# STM32F030C6T6 register map
File version: 1.0
Registers are 32-bit, access not given, reset 0x0 unless marked. A register's access mark holds for its fields unless they carry their own. Offsets are from the block's base; [hi:lo] are bit positions; {n}, {i} and the like mark numbered series.

## I2C1
Base 0x40005400
Same registers: I2C2 0x40005800
0x00 CR1
  [23] PECEN, [22] ALERTEN, [21] SMBDEN, [20] SMBHEN, [19] GCEN, [17] NOSTRETCH, [16] SBC, [15] RXDMAEN, [14] TXDMAEN, [31:13] s, [12] ANFOFF, [11:8] DNF, [7] ERRIE, [6] TCIE, [5] STOPIE, [4] NACKIE, [3] ADDRIE, [2] RXIE, [1] TXIE, [0] PE
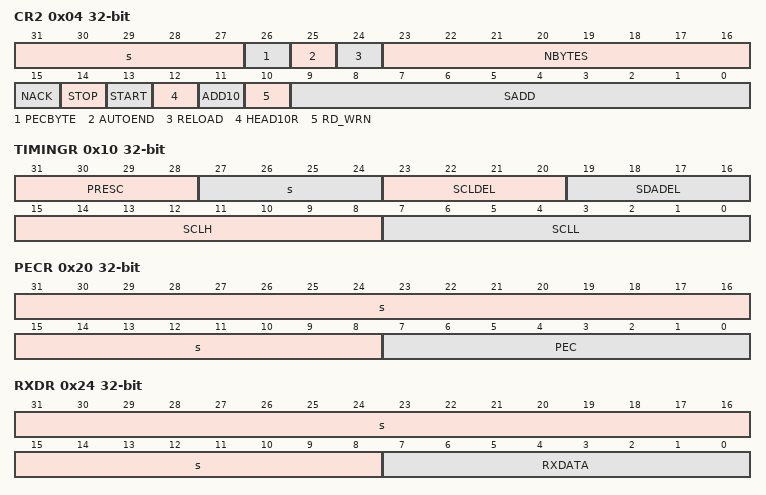
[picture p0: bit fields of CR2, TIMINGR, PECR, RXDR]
0x04 CR2
  [31:27] s, [26] PECBYTE, [25] AUTOEND, [24] RELOAD, [23:16] NBYTES, [15] NACK, [14] STOP, [13] START, [12] HEAD10R, [11] ADD10, [10] RD_WRN, [9:0] SADD
0x08 OAR1
  [15] OA1EN, [31:11] s, [10] OA1MODE, [9:0] OA1
0x0C OAR2
  [15] OA2EN, [10:8] OA2MSK, [7:1] OA2, [31:0] s
0x10 TIMINGR
  [31:28] PRESC, [27:24] s, [23:20] SCLDEL, [19:16] SDADEL, [15:8] SCLH, [7:0] SCLL
0x14 TIMEOUTR
  [31] TEXTEN, [27:16] TIMEOUTB, [15] TIMOUTEN, [30:13] s, [12] TIDLE, [11:0] TIMEOUTA
0x18 ISR
  [23:17] ADDCODE, [16] DIR, [15] BUSY, [31:14] s, [13] ALERT, [12] TIMEOUT, [11] PECERR, [10] OVR, [9] ARLO, [8] BERR, [7] TCR, [6] TC, [5] STOPF, [4] NACKF, [3] ADDR, [2] RXNE, [1] TXIS, [0] TXE
0x1C ICR
  [13] ALERTCF, [12] TIMOUTCF, [11] PECCF, [10] OVRCF, [9] ARLOCF, [8] BERRCF, [5] STOPCF, [4] NACKCF, [3] ADDRCF, [31:0] s
0x20 PECR
  [31:8] s, [7:0] PEC
0x24 RXDR
  [31:8] s, [7:0] RXDATA
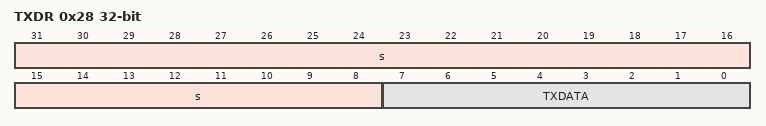
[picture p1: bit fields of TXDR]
0x28 TXDR
  [31:8] s, [7:0] TXDATA

## USB
Base 0x40005C00
Same registers: USB 0x40006000, USB 0x40006000, SRAM 0x40006000
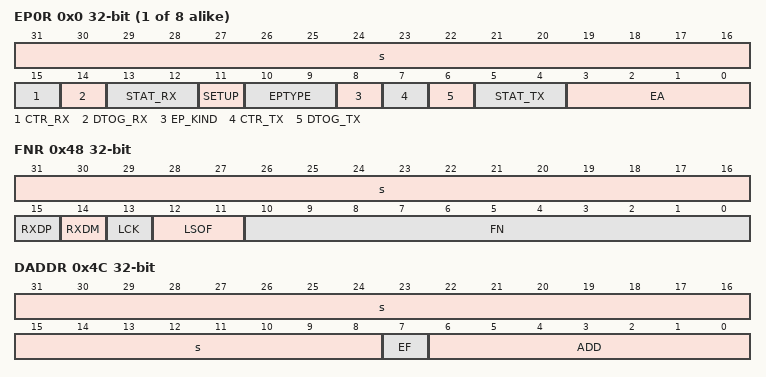
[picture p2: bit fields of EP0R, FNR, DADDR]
{0x0+4i} EP{i}R (i=0..7)
  [31:16] s, [15] CTR_RX, [14] DTOG_RX, [13:12] STAT_RX, [11] SETUP, [10:9] EPTYPE, [8] EP_KIND, [7] CTR_TX, [6] DTOG_TX, [5:4] STAT_TX, [3:0] EA
0x40 CNTR
  [15] CTRM, [14] PMAOVRM, [13] ERRM, [12] WKUPM, [11] SUSPM, [10] RESETM, [9] SOFM, [8] ESOFM, [7] L1REQM, [31:6] s, [5] L1RESUME, [4] RESUME, [3] FSUSP, [2] LPMODE, [1] PDWN, [0] FRES
0x44 ISTR
  [15] CTR, [14] PMAOVR, [13] ERR, [12] WKUP, [11] SUSP, [10] RESET, [9] SOF, [8] ESOF, [7] L1REQ, [31:5] s, [4] DIR, [3:0] EP_ID
0x48 FNR
  [31:16] s, [15] RXDP, [14] RXDM, [13] LCK, [12:11] LSOF, [10:0] FN
0x4C DADDR
  [31:8] s, [7] EF, [6:0] ADD
0x50 BTABLE
  [15:3] BTABLE, [31:0] s
0x54 LPMCSR
  [7:4] BESL, [3] REMWAKE, [31:2] s, [1] LPMACK, [0] LPMEN
0x58 BCDR
  [15] DPPU, [31:8] s, [7] PS2DET, [6] SDET, [5] PDET, [4] DCDET, [3] SDEN, [2] PDEN, [1] DCDEN, [0] BCDEN

## PWR
Base 0x40007000
0x00 CR
  [8] DBP, [31:4] s, [3] CSBF, [2] CWUF, [1] PDDS, [0] LPDS
0x04 CSR
  [n+7] EWUP{n} (n=4..7), [9] EWUP2, [8] EWUP1, [31:2] s, [1] SBF, [0] WUF

## SYSCFG
Base 0x40010000
0x00 CFGR1
  [26] USART3_DMA_RMP, [23] I2C_PA10_FMP, [22] I2C_PA9_FMP, [20] I2C1_FMP, [n+10] I2C_PB{n}_FMP (n=6..9), [12] TIM17_DMA_RMP, [11] TIM16_DMA_RMP, [10] USART1_RX_DMA_RMP, [9] USART1_TX_DMA_RMP, [8] ADC_DMA_RMP, [4] PA11_PA12_RMP, [31:2] s, [1:0] MEM_MODE
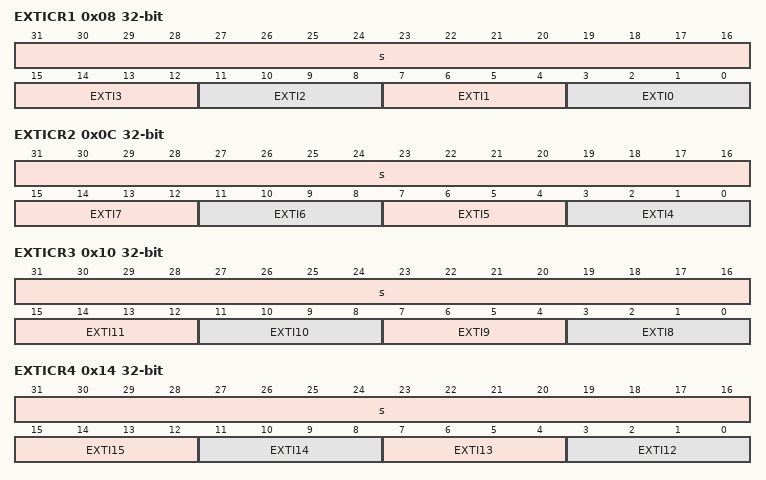
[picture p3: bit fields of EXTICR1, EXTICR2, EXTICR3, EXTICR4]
0x08 EXTICR1
  [31:16] s, [4n+3:4n] EXTI{n} (n=0..3)
0x0C EXTICR2
  [31:16] s, [4n-13:4n-16] EXTI{n} (n=4..7)
0x10 EXTICR3
  [31:16] s, [4n-29:4n-32] EXTI{n} (n=8..11)
0x14 EXTICR4
  [31:16] s, [4n-45:4n-48] EXTI{n} (n=12..15)
0x18 CFGR2
  [8] SRAM_PEF, [31:2] s, [1] SRAM_PARITY_LOCK, [0] LOCUP_LOCK

## EXTI
Base 0x40010400
0x00 IMR
  [31:0] IM
0x04 EMR
  [31:0] EM
0x08 RTSR
  [31] RT31, [n] RT{n} (n=19..23), [30:18] s, [17:0] RT
0x0C FTSR
  [31] FT31, [n] FT{n} (n=19..23), [30:18] s, [17:0] FT
0x10 SWIER
  [31] SWI31, [n] SWI{n} (n=19..23), [30:18] s, [17:0] SWI
0x14 PR
  [31] PIF31, [n] PIF{n} (n=19..23), [30:18] s, [17:0] PIF

## ADC
Base 0x40012400
0x00 ISR
  [7] AWD, [31:5] s, [4] OVR, [3] EOSEQ, [2] EOC, [1] EOSMP, [0] ADRDY
0x04 IER
  [7] AWDIE, [31:5] s, [4] OVRIE, [3] EOSEQIE, [2] EOCIE, [1] EOSMPIE, [0] ADRDYIE
0x08 CR
  [31] ADCAL, [4] ADSTP, [30:3] s, [2] ADSTART, [1] ADDIS, [0] ADEN
0x0C CFGR1
  [30:26] AWDCH, [23] AWDEN, [22] AWDSGL, [16] DISCEN, [15] AUTOFF, [14] WAIT, [13] CONT, [12] OVRMOD, [11:10] EXTEN, [31:9] s, [8:6] EXTSEL, [5] ALIGN, [4:3] RES, [2] SCANDIR, [1] DMACFG, [0] DMAEN
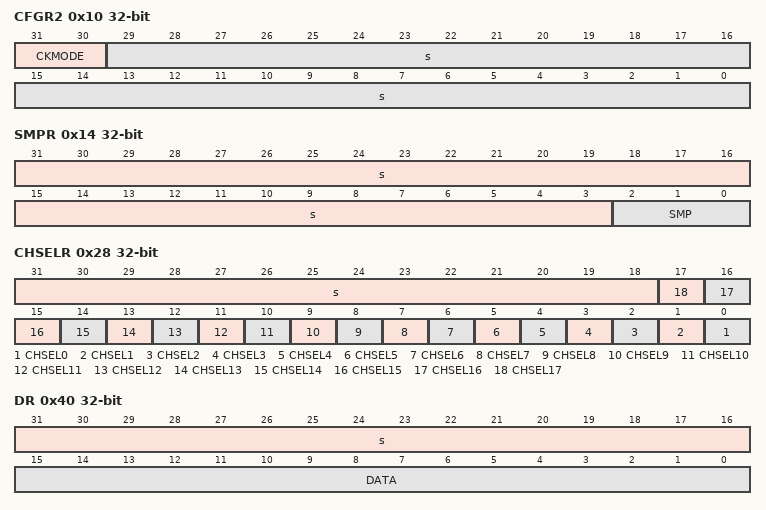
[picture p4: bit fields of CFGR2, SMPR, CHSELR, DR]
0x10 CFGR2
  [31:30] CKMODE, [29:0] s
0x14 SMPR
  [31:3] s, [2:0] SMP
0x20 TR
  [27:16] HT, [31:12] s, [11:0] LT
0x28 CHSELR
  [31:18] s, [n] CHSEL{n} (n=0..17)
0x40 DR
  [31:16] s, [15:0] DATA
0x308 CCR
  [23] TSEN, [22] VREFEN, [31:0] s
